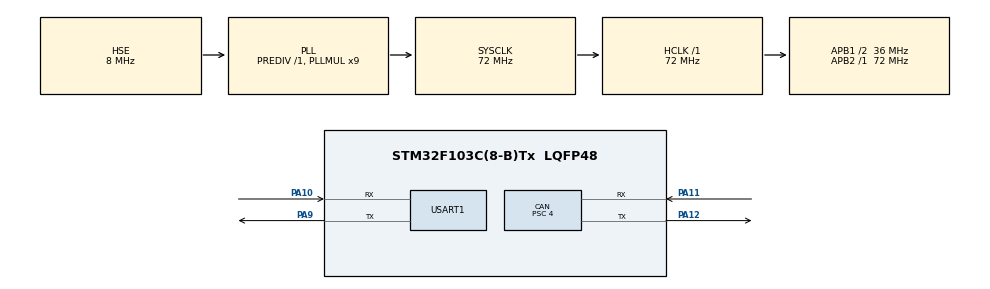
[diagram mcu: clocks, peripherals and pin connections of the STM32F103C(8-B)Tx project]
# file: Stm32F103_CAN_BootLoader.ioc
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CAN.BS1=CAN_BS1_13TQ
CAN.BS2=CAN_BS2_4TQ
CAN.CalculateBaudRate=500000
CAN.CalculateTimeBit=2000
CAN.CalculateTimeQuantum=111.11111111111111
CAN.Prescaler=4
Mcu.Family=STM32F1
Mcu.Name=STM32F103C(8-B)Tx
Mcu.Package=LQFP48
NVIC.CAN1_RX1_IRQn=true\:0\:0\:false\:false\:true\:true\:true\:true
NVIC.CAN1_SCE_IRQn=true\:0\:0\:false\:false\:true\:true\:true\:true
NVIC.PriorityGroup=NVIC_PRIORITYGROUP_4
NVIC.USB_HP_CAN1_TX_IRQn=true\:0\:0\:false\:false\:true\:true\:true\:true
NVIC.USB_LP_CAN1_RX0_IRQn=true\:0\:0\:false\:false\:true\:true\:true\:true
PA10.Mode=Asynchronous
PA10.Signal=USART1_RX
PA11.Mode=CAN_Activate
PA11.Signal=CAN_RX
PA12.Mode=CAN_Activate
PA12.Signal=CAN_TX
PA13.Mode=Serial_Wire
PA13.Signal=SYS_JTMS-SWDIO
PA14.Mode=Serial_Wire
PA14.Signal=SYS_JTCK-SWCLK
PA9.Mode=Asynchronous
PA9.Signal=USART1_TX
PC14-OSC32_IN.Mode=LSE-External-Oscillator
PC14-OSC32_IN.Signal=RCC_OSC32_IN
PC15-OSC32_OUT.Mode=LSE-External-Oscillator
PC15-OSC32_OUT.Signal=RCC_OSC32_OUT
PD0-OSC_IN.Mode=HSE-External-Oscillator
PD0-OSC_IN.Signal=RCC_OSC_IN
PD1-OSC_OUT.Mode=HSE-External-Oscillator
PD1-OSC_OUT.Signal=RCC_OSC_OUT
ProjectManager.HeapSize=0x200
ProjectManager.StackSize=0x400
ProjectManager.TargetToolchain=MDK-ARM V5.32
RCC.AHBFreq_Value=72000000
RCC.APB1CLKDivider=RCC_HCLK_DIV2
RCC.APB1Freq_Value=36000000
RCC.APB1TimFreq_Value=72000000
RCC.APB2Freq_Value=72000000
RCC.APB2TimFreq_Value=72000000
RCC.HCLKFreq_Value=72000000
RCC.PLLMUL=RCC_PLL_MUL9
RCC.PLLSourceVirtual=RCC_PLLSOURCE_HSE
RCC.SYSCLKFreq_VALUE=72000000
RCC.SYSCLKSource=RCC_SYSCLKSOURCE_PLLCLK
RCC.USBFreq_Value=72000000
USART1.VirtualMode=VM_ASYNC
board=custom

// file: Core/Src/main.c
/* USER CODE BEGIN Header */
/**
  ******************************************************************************
  * @file           : main.c
  * @brief          CAN bootloader entry + 1 Hz alive frame.
  ******************************************************************************
  */
/* USER CODE END Header */
#include "main.h"
#include "can.h"
#include "usart.h"
#include "gpio.h"

/* USER CODE BEGIN Includes */
#include "bl_flash.h"
#include "bl_can.h"
#include "bl_app_jump.h"
#include "bl_config.h"
#include "bl_request.h"
/* USER CODE END Includes */

/* USER CODE BEGIN PV */
extern CAN_HandleTypeDef hcan;
/* USER CODE END PV */

void SystemClock_Config(void);

int main(void)
{

  HAL_Init();

  SystemClock_Config();

  MX_GPIO_Init();
  MX_CAN_Init();
  MX_USART1_UART_Init();

  /* USER CODE BEGIN 2 */
  HAL_GPIO_WritePin(GPIOC, GPIO_PIN_13, GPIO_PIN_SET); /* LED off (active-low) */

  (void)bl_flash_init();
  if (!bl_can_init()) {
    while (1) {
      HAL_GPIO_TogglePin(GPIOC, GPIO_PIN_13);
      HAL_Delay(100);
    }
  }

  /* Upgrade request from APP (SRAM magic + SystemReset) → stay in BL.
   * Otherwise jump APP immediately. APP detects 0x700 and returns here. */
  if (!bl_request_consume_update_flag() && bl_app_is_valid()) {
    bl_app_jump();
  }
  /* USER CODE END 2 */

  while (1)
  {

    /* USER CODE BEGIN 3 */
    bl_can_poll(); /* BL idle: waiting for CAN update, or no valid APP */
  }
  /* USER CODE END 3 */
}

void SystemClock_Config(void)
{
  RCC_OscInitTypeDef RCC_OscInitStruct = {0};
  RCC_ClkInitTypeDef RCC_ClkInitStruct = {0};

  RCC_OscInitStruct.OscillatorType = RCC_OSCILLATORTYPE_HSE;
  RCC_OscInitStruct.HSEState = RCC_HSE_ON;
  RCC_OscInitStruct.HSEPredivValue = RCC_HSE_PREDIV_DIV1;
  RCC_OscInitStruct.HSIState = RCC_HSI_ON;
  RCC_OscInitStruct.PLL.PLLState = RCC_PLL_ON;
  RCC_OscInitStruct.PLL.PLLSource = RCC_PLLSOURCE_HSE;
  RCC_OscInitStruct.PLL.PLLMUL = RCC_PLL_MUL9;
  if (HAL_RCC_OscConfig(&RCC_OscInitStruct) != HAL_OK) {
    Error_Handler();
  }

  RCC_ClkInitStruct.ClockType = RCC_CLOCKTYPE_HCLK | RCC_CLOCKTYPE_SYSCLK
                              | RCC_CLOCKTYPE_PCLK1 | RCC_CLOCKTYPE_PCLK2;
  RCC_ClkInitStruct.SYSCLKSource = RCC_SYSCLKSOURCE_PLLCLK;
  RCC_ClkInitStruct.AHBCLKDivider = RCC_SYSCLK_DIV1;
  RCC_ClkInitStruct.APB1CLKDivider = RCC_HCLK_DIV2;
  RCC_ClkInitStruct.APB2CLKDivider = RCC_HCLK_DIV1;
  if (HAL_RCC_ClockConfig(&RCC_ClkInitStruct, FLASH_LATENCY_2) != HAL_OK) {
    Error_Handler();
  }
}

void Error_Handler(void)
{
  __HAL_RCC_GPIOC_CLK_ENABLE();
  {
    GPIO_InitTypeDef g = {0};
    g.Pin = GPIO_PIN_13;
    g.Mode = GPIO_MODE_OUTPUT_PP;
    g.Speed = GPIO_SPEED_FREQ_LOW;
    HAL_GPIO_Init(GPIOC, &g);
  }
  while (1) {
    HAL_GPIO_TogglePin(GPIOC, GPIO_PIN_13);
    for (volatile uint32_t i = 0; i < 300000u; i++) {
    }
  }
}
